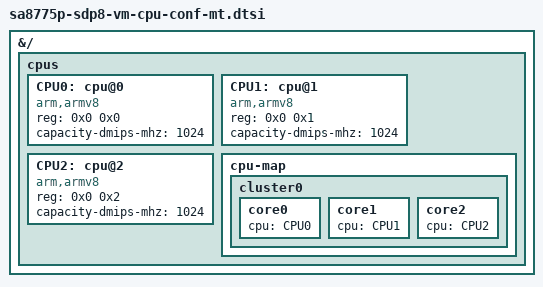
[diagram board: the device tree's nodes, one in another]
// SPDX-License-Identifier: BSD-3-Clause
/*
 * Copyright (c) Qualcomm Technologies, Inc. and/or its subsidiaries.
 */

&{/} {
	cpus {
		#address-cells = <2>;
		#size-cells = <0>;

		CPU0: cpu@0 {
			device_type = "cpu";
			compatible = "arm,armv8";
			reg = <0x0 0x0>;
			capacity-dmips-mhz = <1024>;
		};

		CPU1: cpu@1 {
			device_type = "cpu";
			compatible = "arm,armv8";
			reg = <0x0 0x1>;
			capacity-dmips-mhz = <1024>;
		};

		CPU2: cpu@2 {
			device_type = "cpu";
			compatible = "arm,armv8";
			reg = <0x0 0x2>;
			capacity-dmips-mhz = <1024>;
		};

		cpu-map {
			cluster0 {
				core0 {
					cpu = <&CPU0>;
				};

				core1 {
					cpu = <&CPU1>;
				};

				core2 {
					cpu = <&CPU2>;
				};
			};
		};
	};
};
